# AC7802x register map
Vendor: AutoChips; Series: AC78; File version: 1.0
CPU: CM0PLUS r0p1, little endian, no MPU, no FPU, VTOR, 2 interrupt priority bits
Registers are 32-bit, read-write, reset 0x0 unless marked. A register's access mark holds for its fields unless they carry their own. Offsets are from the block's base; [hi:lo] are bit positions; lines under a group give offsets from that group.

## TIMER_CHANNEL0 — Timer channel
Base 0x40011100
Same registers: TIMER_CHANNEL1 0x40011110, TIMER_CHANNEL2 0x40011120, TIMER_CHANNEL3 0x40011130
0x00 LDVAL — Timer Load Value Register
  [31:0] LDVAL — Timer Load Value
0x04 CVAL ro — Timer Current Count Value Register
  [31:0] CVAL — Timer Current Count Value
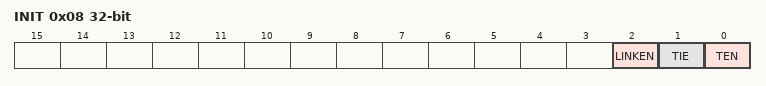
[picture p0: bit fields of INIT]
0x08 INIT — Timer Initialize Control Register
  [2] LINKEN — Timer Link Mode Enable
    0=Timer is not linked,Timer is seperated; 1=Timer is Linked to previous timer
  [1] TIE — Timer Channel Interrupt Enable
    0=Interrupt disabled; 1=Interrupt enabled
  [0] TEN — Timer Channel Enable
    0=Timer channel disabled; 1=Timer channel enabled
0x0C TF — Timer Flag Register
  [0] TIF — Timer Status Flag
    0=Timeout has not yet occurred; 1=Timeout has occurred

## CTU — Connect Module Unit
Base 0x40016000
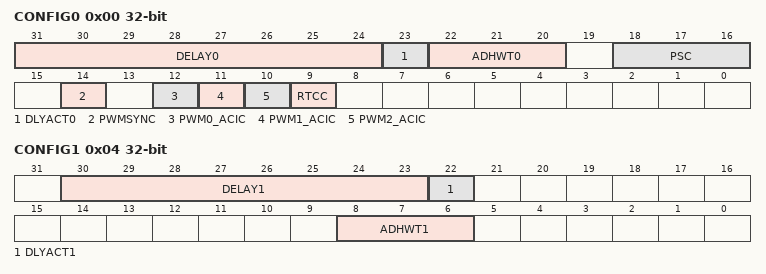
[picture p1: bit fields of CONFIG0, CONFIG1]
0x00 CONFIG0 — CTU Configuration Register 0
  [31:24] DELAY0 — Regular Group Trigger Delay Counter
  [23] DLYACT0 ro — Regular Group Trigger Delay Active
    0=Delay0 is inactive; 1=Delay0 is active
  [22:20] ADHWT0 — ADC Hardware Trigger Source for regular group
    0=RTC Overflow as ADC hardware Trigger; 1=PWM0 Init as ADC Hardware Trigger; 2=PWM0 Match Trigger with 8-bit programmable counter delay; 3=PWM2 Init as ADC Hardware Trigger; 4=PWM2 Match Trigger with 8-bit programmable counter delay; 5=Timer Channel0 overflow as ADC hardware Trigger; 6=Timer Channel1 overflow as ADC Hardware Trigger; 7=ACMP0 Out as ADC Hardware Trigger
  [18:16] PSC — Clock Prescaler
    0=Clock divided by 1; 1=Clock divided by 2; 2=Clock divided by 4; 3=Clock divided by 8; 4=Clock divided by 16; 5=Clock divided by 32; 6=Clock divided by 64; 7=Clock divided by 128
  [14] PWMSYNC — PWM SW Synchronization Selection
    0=No Synchronization triggered; 1=Generate PWM Synchronization to trigger PWM Modules
  [12] PWM0_ACIC — Analog Comparator to Input Capture Enable
    0=ACMP0 Output is not connected to PWM0 Channel0; 1=ACMP0 Output is connected to PWM0 Channel0
  [11] PWM1_ACIC — Analog Comparator to Input Capture Enable
    0=ACMP0 Output is not connected to PWM1 Channel0; 1=ACMP0 Output is connected to PWM1 Channel0
  [10] PWM2_ACIC — Analog Comparator to Input Capture Enable
    0=ACMP0 Output is not connected to PWM2 Channel0; 1=ACMP0 Output is connected to PWM2 Channel0
  [9] RTCC — Real-Time Counter Capture
    0=RTC Overflow is not connected to PWM1 Channel 1; 1=RTC overflow is connected to PWM1 Channel 1
0x04 CONFIG1 — CTU Configuration Register 1
  [30:23] DELAY1 — Injection Group Trigger Delay Counter
  [22] DLYACT1 ro — Injection Group Trigger Delay Active
    0=Delay1 is inactive; 1=Delay1 is active
  [8:6] ADHWT1 — ADC Hardware Trigger Source for injection group
    0=RTC Overflow as the ADC hardware trigger; 1=PWM0 Init as ADC Hardware Trigger; 2=PWM0 Match Trigger with 8-bit programmable counter delay; 3=PWM2 Init as ADC Hardware Trigger; 4=PWM2 Match Trigger with 8-bit programmable counter delay; 5=Timer Channel0 overflow as the ADC hardware trigger; 6=Timer Channel1 overflow as the ADC hardware trigger; 7=ACMP0 output as the ADC hardware trigger

## WDG — Watchdog
Base 0x4000B000
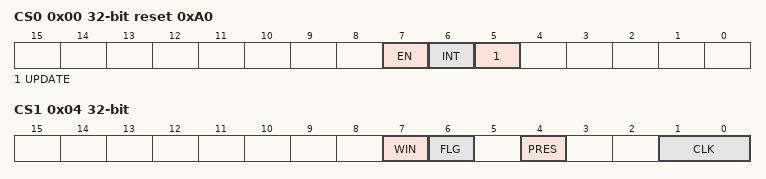
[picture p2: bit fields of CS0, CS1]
0x00 CS0 reset 0xA0 — Watchdog Control and Status Register 0
  [7] EN — Watchdog Enable
    0=Watchdog disabled; 1=Watchdog enabled
  [6] INT — Watchdog Interrupt Enable
    0=Watchdog interrupts are disabled. Watchdog resets are not delayed.; 1=Watchdog interrupts are enabled. Watchdog resets are delayed by 128 bus clocks.
  [5] UPDATE — Allow Updates WDG Config
    0=Updates not allowed. After the initial configuration, the watchdog cannot be later modified without forcing a reset.; 1=Updates allowed. Software can modify the watchdog configuration registers within 128 bus clocks after performing the unlock write sequence.
0x04 CS1 — Watchdog Control and Status Register 1
  [7] WIN — Watchdog Window
    0=Window mode disabled; 1=Window mode enabled
  [6] FLG — Watchdog Interrupt Flag
    0=No interrupt occurred; 1=An interrupt occurred
  [4] PRES — Watchdog Prescalar
    0=256 prescalar disabled; 1=256 prescalar enabled
  [1:0] CLK — Watchdog Clock Source
    0=Bus clock; 1=Internal 32kHz LSI; 2=Internal 32MHz HSI; 3=External XOSC
0x08 CNT — Watchdog Counter Value
  [31:0] CNT — Counter Value
0x0C TOVAL reset 0x271000 — Watchdog Timeout Value Register
  [31:0] TOVAL — Timeout Value
0x10 WIN — Watchdog Window Register
  [31:0] WIN — Window Value

## RTC — Real-time counter
Base 0x40008400
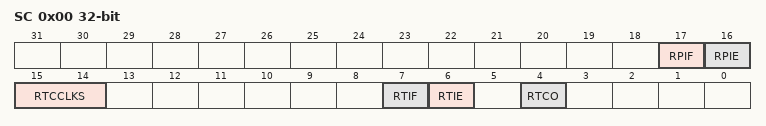
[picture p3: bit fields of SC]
0x00 SC — RTC Status and Control Register
  [17] RPIF — RTC Prescaler Interrupt Flag
  [16] RPIE — RTC Prescaler Interrupt Enable
  [15:14] RTCCLKS — RTC Clock Source Select
    0=Bus Clock; 1=Interval 32KHz; 2=External XOSC; 3=External Pin In
  [7] RTIF — RTC Interrupt Flag
  [6] RTIE — RTC Interrupt Enable
  [4] RTCO — RTC Counter Output Enable
0x04 MOD — RTC Modulo Value
  [31:0] MOD — Modulo Value
0x08 CNT ro — RTC Count Value
  [31:0] CNT — Count Value
0x0C PS — RTC Prescaler Register
  [19:0] RTCPS — Prescale Value
0x10 PSCNT ro — RTC Prescaler Counter Register
  [19:0] PSCNT — Prescaler Counter Register

## ECC_SRAM — SRAM Error Check and Correction
Base 0x40000020
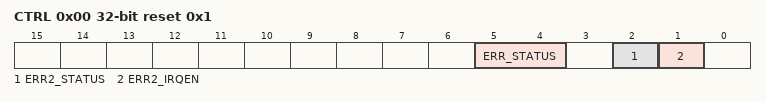
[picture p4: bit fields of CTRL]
0x00 CTRL reset 0x1 (reset mask 0x0) — SRAM ECC status and control register
  [5:4] ERR_STATUS — ECC (2bit/1)bit error status
    0=ECC has no error; 1=ECC 2 bit error is active; 2=ECC 1 bit error is active; 3=ECC 1 bit error is active
  [2] ERR2_STATUS ro — ECC 2 bit error status
    0=ECC 2 bit error is inactive; 1=ECC 2 bit error is active
  [1] ERR2_IRQEN — ECC 2 bit error interrupt enable
    0=ECC 2 bit error interrupt disabled; 1=ECC 2 bit error interrupt enabled
0x04 ERR1_ADDR ro reset not defined — ECC 1 bit error address
  [12:0] ERR1_ADDR — ECC 1 bit Error Address
0x08 ERR2_ADDR ro reset not defined — ECC 2 bit error address
  [12:0] ERR2_ADDR — ECC 2 bit Error Address
